# CPUSS_1.0 register map
Vendor: Texas Instruments
Peripheral module from a debugger description file (folder mspm0l11xx_l13xx).
Registers are 32-bit, read-write, no defined reset value unless marked. A register's access mark holds for its fields unless they carry their own. Offsets are as the file gives them; lines under a group give offsets from that group; [hi:lo] are bit positions; {n}, {i} and the like mark numbered series; 'fields as' and 'values as' point back to an identical list; <NAME> marks a mode.

## CPUSS
0x10E0 CPUSS_EVT_MODE ro — Event Mode
  [1:0] INT_CFG — Event line mode select
    0=DISABLE (The interrupt or event line is disabled.); 1=SOFTWARE (Event handled by software. Software must clear the associated RIS flag.); 2=HARDWARE (Event handled by hardware. The hardware (another module) clears automatically the associated RIS flag.)
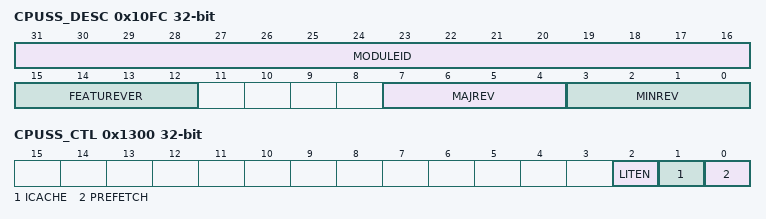
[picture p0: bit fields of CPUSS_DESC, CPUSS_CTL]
0x10FC CPUSS_DESC ro — Module Description
  [31:16] MODULEID — Module identification contains a unique peripheral identification number. The assignments are maintained in a central database for all of the platform modules to ensure uniqueness.
  [15:12] FEATUREVER — Feature Set for the module *instance*
  [7:4] MAJREV — Major rev of the IP
  [3:0] MINREV — Minor rev of the IP
0x1100 CPUSS_INT_GROUP0 group
  0x00 CPUSS_INT_GROUP0_IIDX ro — Interrupt index
    [7:0] STAT — Interrupt index status
      0=NO_INTR (No pending interrupt); {v}=INT{v-1} (Interrupt {v-1}) (v=1..8)
  0x08 CPUSS_INT_GROUP0_IMASK ro — Interrupt mask
    [7:0] INT — Masks the corresponding interrupt
      0=CLR (Interrupt is masked out); 1=SET (Interrupt will request an interrupt service routine and corresponding bit in MIS will be set)
  0x10 CPUSS_INT_GROUP0_RIS — Raw interrupt status
    [7:0] INT — Raw interrupt status for INT
      0=CLR (INT0 did not occur.); 1=SET (INT0 occurred.)
  0x18 CPUSS_INT_GROUP0_MIS — Masked interrupt status
    [0] INT — Masked interrupt status for INT0
      0=CLR (INT does not request an interrupt service routine); 1=SET (INT requests an interrupt service routine)
  0x20 CPUSS_INT_GROUP0_ISET — Interrupt set
    [0] INT — Sets INT in RIS register
      0=NO_EFFECT (Writing a 0 has no effect); 1=SET (RIS bit corresponding to INT is set)
  0x28 CPUSS_INT_GROUP0_ICLR — Interrupt clear
    [0] INT — Clears INT in RIS register
      0=NO_EFFECT (Writing a 0 has no effect); 1=CLR (RIS bit corresponding to INT is cleared)
0x1130 CPUSS_INT_GROUP1 group
  0x00 CPUSS_INT_GROUP1_IIDX ro — Interrupt index
    fields as CPUSS_INT_GROUP0.CPUSS_INT_GROUP0_IIDX
  0x08 CPUSS_INT_GROUP1_IMASK ro — Interrupt mask
    fields as CPUSS_INT_GROUP0.CPUSS_INT_GROUP0_IMASK
  0x10 CPUSS_INT_GROUP1_RIS — Raw interrupt status
    [0] INT — Raw interrupt status for INT
      0=CLR (INT0 did not occur.); 1=SET (INT0 occurred.)
  0x18 CPUSS_INT_GROUP1_MIS — Masked interrupt status
    fields as CPUSS_INT_GROUP0.CPUSS_INT_GROUP0_MIS
  0x20 CPUSS_INT_GROUP1_ISET — Interrupt set
    fields as CPUSS_INT_GROUP0.CPUSS_INT_GROUP0_ISET
  0x28 CPUSS_INT_GROUP1_ICLR — Interrupt clear
    fields as CPUSS_INT_GROUP0.CPUSS_INT_GROUP0_ICLR
0x1300 CPUSS_CTL — Prefetch/Cache control
  [2] LITEN — Literal caching and prefetch enable. This bit is a subset of ICACHE/PREFETCH bit i.e. literal caching or literal prefetching will only happen if ICACHE or PREFETCH bits have been set respectively When enabled, the cache and prefetcher structures inside CPUSS will cache and prefetch literals When disabled, the cache and prefetcher structures inside CPUSS will not cache and prefetch literals
    0=DISABLE (Literal caching disabled); 1=ENABLE (Literal caching enabled)
  [1] ICACHE — Used to enable/disable Instruction caching on flash access.
    0=DISABLE (Disable instruction caching.); 1=ENABLE (Enable instruction caching.)
  [0] PREFETCH — Used to enable/disable instruction prefetch to Flash.
    0=DISABLE (Disable instruction prefetch.); 1=ENABLE (Enable instruction prefetch.)
